# STM32H553xx register map
File version: 1.0
Registers are 32-bit, read-write, reset 0x0 unless marked. A register's access mark holds for its fields unless they carry their own. Offsets are from the block's base; [hi:lo] are bit positions; {n}, {i} and the like mark numbered series.

## DTS
Base 0x40008C00
Same registers: DTS_S 0x50008C00
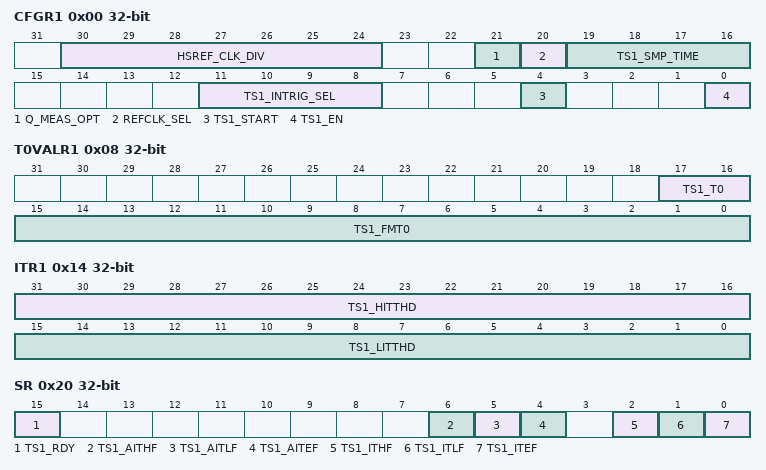
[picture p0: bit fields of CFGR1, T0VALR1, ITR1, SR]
0x00 CFGR1 — DTS configuration register
  [30:24] HSREF_CLK_DIV — High Speed Clock Divider Ratio [6:0]
  [21] Q_MEAS_OPT — Quick measure option bit
  [20] REFCLK_SEL — Reference Clock Selection
  [19:16] TS1_SMP_TIME — Sample time [3:0] for DTS
  [11:8] TS1_INTRIG_SEL — Input triggers selection bits [3:0] for DTS
  [4] TS1_START — Proceed to a frequency measurement on DTS
  [0] TS1_EN — DTS Enable
0x08 T0VALR1 — DTS T0 Value register
  [17:16] TS1_T0 — Engineering value of the DTSerature T0 for DTS
  [15:0] TS1_FMT0 — Engineering value of the measured frequency at T0 for DTS
0x10 RAMPVALR — DTS Ramp value register
  [15:0] TS1_RAMP_COEFF — Engineering value of the ramp coefficient for DTS
0x14 ITR1 — DTS Interrupt threshold register
  [31:16] TS1_HITTHD — High interrupt threshold[15:0] for DTS
  [15:0] TS1_LITTHD — Low interrupt threshold[15:0] for DTS
0x1C DR — DTS data register
  [15:0] TS1_MFREQ — Measured Frequency[15:0] for DTS
0x20 SR — DTS status register
  [15] TS1_RDY — DTS ready flag
  [6] TS1_AITHF — Asynchronous interrupt flag for high threshold for DTS
  [5] TS1_AITLF — Asynchronous interrupt flag for low threshold for DTS
  [4] TS1_AITEF — Asynchronous interrupt flag for end of measure for DTS
  [2] TS1_ITHF — Interrupt flag for high threshold for DTS
  [1] TS1_ITLF — Interrupt flag for low threshold for DTS
  [0] TS1_ITEF — Interrupt flag for end of measure for DTS
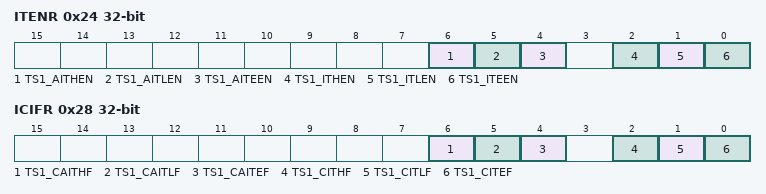
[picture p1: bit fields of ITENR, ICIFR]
0x24 ITENR — DTS Interrupt enable register
  [6] TS1_AITHEN — Enable asynchronous interrupt flag for high threshold for DTS
  [5] TS1_AITLEN — Enable Asynchronous interrupt flag for low threshold for DTS
  [4] TS1_AITEEN — Enable asynchronous interrupt flag for end of measure for DTS
  [2] TS1_ITHEN — Enable interrupt flag for high threshold for DTS
  [1] TS1_ITLEN — Enable interrupt flag for low threshold for DTS
  [0] TS1_ITEEN — Enable interrupt flag for end of measure for DTS
0x28 ICIFR — DTS Clear Interrupt flag register
  [6] TS1_CAITHF — Clear the asynchronous IT flag for high threshold on DTS
  [5] TS1_CAITLF — Clear the asynchronous IT flag for low threshold for DTS
  [4] TS1_CAITEF — Clear the asynchronous IT flag for End Of Measure for DTS
  [2] TS1_CITHF — Clear the IT flag for high threshold on DTS
  [1] TS1_CITLF — Clear the IT flag for low threshold for DTS
  [0] TS1_CITEF — Clear the IT flag for End Of Measure for DTS
0x2C OR — DTS option register 1

## FDCAN_CONFIG — FD Controller Area Network Configuration
Base 0x4000A500
Same registers: FDCAN_CONFIG_S 0x5000A500
0x00 CKDIV — FDCAN clock divider register
  [3:0] PDIV — Input Clock Divider
0x204 OPTR — FDCAN option register
0x2F0 HWCFG — FDCAN hardware configuration register
0x2F4 VERR — FDCAN IP version register
0x2F8 IPIDR — FDCAN IP ID register
0x2FC SIDR — FDCAN size ID register

## USB_DRD_FS — Universal Serial Bus Full Speed Dual Role Device
Base 0x40016000
Same registers: USB_DRD_FS_S 0x50016000
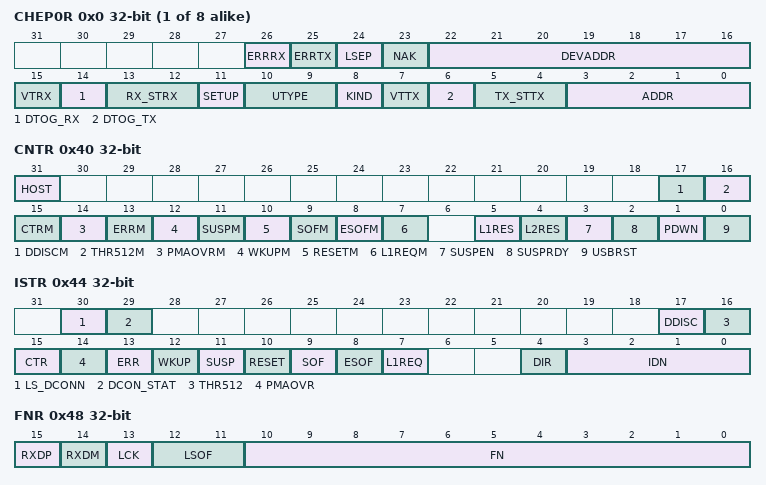
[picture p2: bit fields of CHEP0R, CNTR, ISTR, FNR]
{0x0+4i} CHEP{i}R (i=0..7) — USB Channel/Endpoint {i} register
  [26] ERRRX — Receive error
  [25] ERRTX — Transmit error
  [24] LSEP — Low Speed Endpoint (host with Hub Only)
  [23] NAK — Previous NAK detected
  [22:16] DEVADDR
  [15] VTRX — USB valid transaction received Mask
  [14] DTOG_RX — Data Toggle, for reception transfers Mask
  [13:12] RX_STRX — Status bits, for reception transfers Mask
  [11] SETUP — Setup transaction completed Mask
  [10:9] UTYPE — USB type of transaction Mask
  [8] KIND — EndPoint KIND Mask
  [7] VTTX — Valid USB transaction transmitted Mask
  [6] DTOG_TX — Data Toggle, for transmission transfers Mask
  [5:4] TX_STTX — Status bits, for transmission transfers Mask
  [3:0] ADDR — Endpoint address Mask
0x40 CNTR — Control register
  [31] HOST — Host Mode
  [17] DDISCM — Device disconnection mask
  [16] THR512M — 512byte Threshold interrupt mask
  [15] CTRM — Correct Transfer Mask
  [14] PMAOVRM — DMA OVeR/underrun Mask
  [13] ERRM — ERRor Mask
  [12] WKUPM — WaKe UP Mask
  [11] SUSPM — SUSPend Mask
  [10] RESETM — RESET Mask
  [9] SOFM — Start Of Frame Mask
  [8] ESOFM — Expected Start Of Frame Mask
  [7] L1REQM — LPM L1 state request interrupt Mask
  [5] L1RES — LPM L1 Resume request/ Remote Wakeup Mask
  [4] L2RES — L2 Remote Wakeup / Resume driver Mask
  [3] SUSPEN — Suspend state enable Mask
  [2] SUSPRDY — Suspend state effective Mask
  [1] PDWN — Power DoWN Mask
  [0] USBRST — USB Reset Mask
0x44 ISTR — Interrupt status register
  [30] LS_DCONN — LS_DCONN Mask
  [29] DCON_STAT — Device Connection status (connected/Disconnected) don't cause an interrupt
  [17] DDISC — Device disconnection interrupt
  [16] THR512 — 512byte threshold interrupt (used with isochrnous single buffer )
  [15] CTR — Correct TRansfer (clear-only bit) Mask
  [14] PMAOVR — PMA OVeR/underrun (clear-only bit) Mask
  [13] ERR — ERRor (clear-only bit) Mask
  [12] WKUP — WaKe UP (clear-only bit) Mask
  [11] SUSP — SUSPend (clear-only bit) Mask
  [10] RESET — RESET Mask
  [9] SOF — Start Of Frame (clear-only bit) Mask
  [8] ESOF — Expected Start Of Frame (clear-only bit) Mask
  [7] L1REQ — LPM L1 state request Mask
  [4] DIR — DIRection of transaction (read-only bit) Mask
  [3:0] IDN — EndPoint IDentifier (read-only bit) Mask
0x48 FNR — Frame number register
  [15] RXDP — status of D+ data line Mask
  [14] RXDM — status of D- data line Mask
  [13] LCK — LoCKed Mask
  [12:11] LSOF — Lost SOF Mask
  [10:0] FN — Frame Number Mask
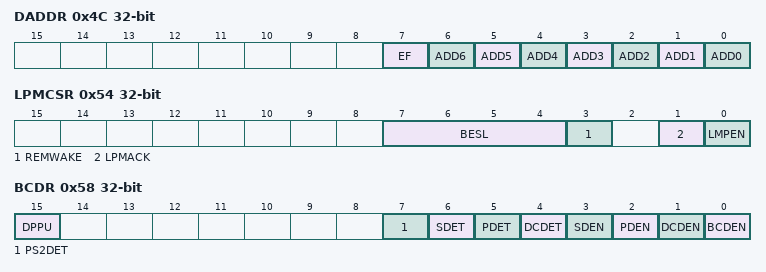
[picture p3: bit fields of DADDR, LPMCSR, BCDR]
0x4C DADDR — Device address register
  [7] EF — Enable Function Mask
  [n] ADD{n} (n=0..6) — Bit {n} Mask
0x54 LPMCSR — LPM Control and Status register
  [7:4] BESL — BESL value received with last ACKed LPM Token Mask
  [3] REMWAKE — bRemoteWake value received with last ACKed LPM Token Mask
  [1] LPMACK — LPM Token acknowledge enable Mask
  [0] LMPEN — LPM support enable Mask
0x58 BCDR — Battery Charging detector register
  [15] DPPU — DP Pull-up Enable Mask
  [7] PS2DET — PS2 port or proprietary charger detected Mask
  [6] SDET — Secondary detection (SD) status Mask
  [5] PDET — Primary detection (PD) status Mask
  [4] DCDET — Data contact detection (DCD) status Mask
  [3] SDEN — Secondary detection (SD) mode enable Mask
  [2] PDEN — Primary detection (PD) mode enable Mask
  [1] DCDEN — Data contact detection (DCD) mode enable Mask
  [0] BCDEN — Battery charging detector (BCD) enable Mask
